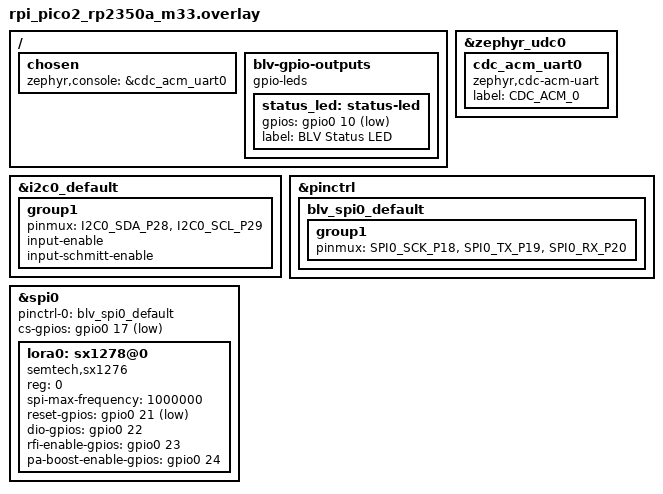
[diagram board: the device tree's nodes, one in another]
/*
 * USB CDC ACM virtual UART for the Raspberry Pi Pico 2.
 */
#include <zephyr/dt-bindings/gpio/gpio.h>

/ {
    chosen {
        zephyr,console = &cdc_acm_uart0;
    };

    blv-gpio-outputs {
        compatible = "gpio-leds";

        status_led: status-led {
            gpios = <&gpio0 10 GPIO_ACTIVE_LOW>;
            label = "BLV Status LED";
        };
    };
};

&zephyr_udc0 {
    status = "okay";

    cdc_acm_uart0: cdc_acm_uart0 {
        compatible = "zephyr,cdc-acm-uart";
        label = "CDC_ACM_0";
    };
};

&i2c0_default {
    group1 {
        pinmux = <I2C0_SDA_P28>, <I2C0_SCL_P29>;
        input-enable;
        input-schmitt-enable;
    };
};

&pinctrl {
    blv_spi0_default: blv_spi0_default {
        group1 {
            pinmux = <SPI0_SCK_P18>,
                     <SPI0_TX_P19>,
                     <SPI0_RX_P20>;
        };
    };
};

&spi0 {
    status = "okay";

    pinctrl-0 = <&blv_spi0_default>;
    pinctrl-names = "default";

    cs-gpios = <&gpio0 17 GPIO_ACTIVE_LOW>;

    lora0: sx1278@0 {
        /*
         * The physical radio is SX1278, but Zephyr 4.3 uses the
         * SX1276-compatible driver for it.
         */
        compatible = "semtech,sx1276";

        reg = <0>;
        spi-max-frequency = <1000000>;

        reset-gpios =
            <&gpio0 21 GPIO_ACTIVE_LOW>;

        dio-gpios =
            <&gpio0 22 (GPIO_PULL_DOWN | GPIO_ACTIVE_HIGH)>;
        
        /*
        * E32-400M30S RXEN on GP23.
        */
        rfi-enable-gpios =
            <&gpio0 23 (GPIO_PULL_DOWN | GPIO_ACTIVE_HIGH)>;
        
         /*
        * E32-400M30S TXEN on GP24.
        * The module uses the SX1278 PA_BOOST transmit path.
        */
        pa-boost-enable-gpios =
            <&gpio0 24 (GPIO_PULL_DOWN | GPIO_ACTIVE_HIGH)>;
    };
};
